# STM32F745 register map
File version: 1.6
CPU: CM7 r0p1, little endian, MPU, FPU, 4 interrupt priority bits
Registers are 32-bit, read-write, reset 0x0 unless marked. A register's access mark holds for its fields unless they carry their own. Offsets are from the block's base; [hi:lo] are bit positions.

## TIM6 — Basic timers
Base 0x40001000
Same registers: TIM7 0x40001400
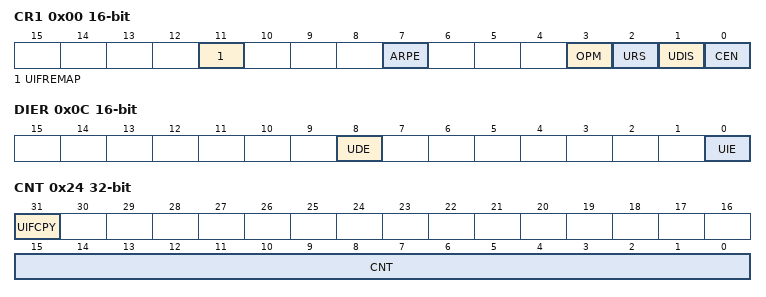
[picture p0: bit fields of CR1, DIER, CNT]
0x00 CR1 16-bit — control register 1
  [11] UIFREMAP — UIF status bit remapping
  [7] ARPE — Auto-reload preload enable
    0=Disabled (TIMx_APRR register is not buffered); 1=Enabled (TIMx_APRR register is buffered)
  [3] OPM — One-pulse mode
    0=Disabled (Counter is not stopped at update event); 1=Enabled (Counter stops counting at the next update event (clearing the CEN bit))
  [2] URS — Update request source
    0=AnyEvent (Any of counter overflow/underflow, setting UG, or update through slave mode, generates an update interrupt or DMA request); 1=CounterOnly (Only counter overflow/underflow generates an update interrupt or DMA request)
  [1] UDIS — Update disable
    0=Enabled (Update event enabled); 1=Disabled (Update event disabled)
  [0] CEN — Counter enable
    0=Disabled (Counter disabled); 1=Enabled (Counter enabled)
0x04 CR2 16-bit — control register 2
  [6:4] MMS — Master mode selection
    0=Reset (Use UG bit from TIMx_EGR register); 1=Enable (Use CNT bit from TIMx_CEN register); 2=Update (Use the update event)
0x0C DIER 16-bit — DMA/Interrupt enable register
  [8] UDE — Update DMA request enable
    0=Disabled (Update DMA request disabled); 1=Enabled (Update DMA request enabled)
  [0] UIE — Update interrupt enable
    0=Disabled (Update interrupt disabled); 1=Enabled (Update interrupt enabled)
0x10 SR 16-bit — status register
  [0] UIF write-0-clears — Update interrupt flag
    on read: 0=NoUpdateOccurred; 1=UpdatePending (Update interrupt pending) | on write: 0=Clear flag
0x14 EGR wo — event generation register
  [0] UG — Update generation
    1=Update (Re-initializes the timer counter and generates an update of the registers.)
0x24 CNT — counter
  [31] UIFCPY ro — UIF copy This bit is a read-only copy of the UIF bit of the TIMx_ISR register. If the UIFREMAP bit in the TIMxCR1 is reset, bit 31 is reserved and read at 0
  [15:0] CNT — Low counter value
0x24 CNT16 16-bit (alternate view of CNT) — 16-bit counter register
  [15:0] CNT — counter value
0x28 PSC 16-bit — prescaler
  [15:0] PSC — Prescaler value
0x2C ARR 16-bit reset 0xFFFF — auto-reload register
  [15:0] ARR — Low Auto-reload value

## Ethernet_MMC — Ethernet: MAC management counters
Base 0x40028100
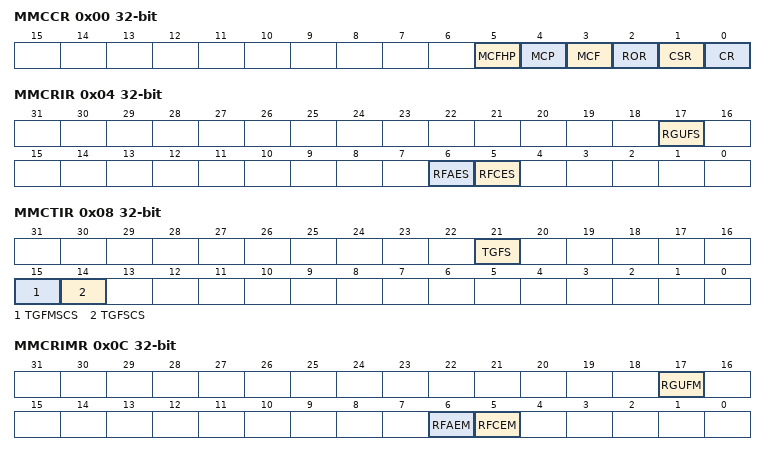
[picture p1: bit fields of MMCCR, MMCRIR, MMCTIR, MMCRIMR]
0x00 MMCCR — Ethernet MMC control register
  [5] MCFHP — MMC counter Full-Half preset
    0=AlmostHalf (When MCP is set, MMC counters are preset to almost-half value 0x7FFF_FFF0); 1=AlmostFull (When MCP is set, MMC counters are preset to almost-full value 0xFFFF_FFF0)
  [4] MCP — MMC counter preset
    1=Preset (MMC counters will be preset to almost full or almost half. Cleared automatically)
  [3] MCF — MMC counter freeze
    0=Unfrozen (All MMC counters update normally); 1=Frozen (All MMC counters frozen to their current value)
  [2] ROR — Reset on read
    0=Disabled (MMC counters do not reset on read); 1=Enabled (MMC counters reset to zero after read)
  [1] CSR — Counter stop rollover
    0=Disabled (Counters roll over to zero after reaching the maximum value); 1=Enabled (Counters do not roll over to zero after reaching the maximum value)
  [0] CR — Counter reset
    1=Reset all counters. Cleared automatically
0x04 MMCRIR — Ethernet MMC receive interrupt register
  [17] RGUFS — Received good Unicast frames status
  [6] RFAES — Received frames alignment error status
  [5] RFCES — Received frames CRC error status
0x08 MMCTIR ro — Ethernet MMC transmit interrupt register
  [21] TGFS — Transmitted good frames status
  [15] TGFMSCS — Transmitted good frames more than single collision status
  [14] TGFSCS — Transmitted good frames single collision status
0x0C MMCRIMR — Ethernet MMC receive interrupt mask register
  [17] RGUFM — Received good Unicast frames mask
    0=Unmasked (Received-good-unicast counter half-full interrupt enabled); 1=Masked (Received-good-unicast counter half-full interrupt disabled)
  [6] RFAEM — Received frames alignment error mask
    0=Unmasked (Received-alignment-error counter half-full interrupt enabled); 1=Masked (Received-alignment-error counter half-full interrupt disabled)
  [5] RFCEM — Received frame CRC error mask
    0=Unmasked (Received-crc-error counter half-full interrupt enabled); 1=Masked (Received-crc-error counter half-full interrupt disabled)
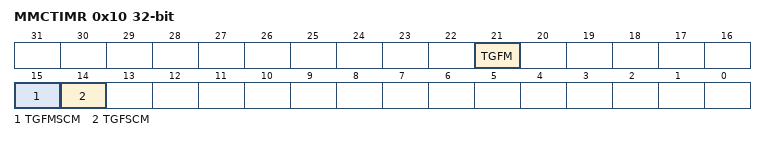
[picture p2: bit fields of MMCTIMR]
0x10 MMCTIMR — Ethernet MMC transmit interrupt mask register
  [21] TGFM — Transmitted good frames mask
    0=Unmasked (Transmitted-good counter half-full interrupt enabled); 1=Masked (Transmitted-good counter half-full interrupt disabled)
  [15] TGFMSCM — Transmitted good frames more than single collision mask
    0=Unmasked (Transmitted-good-multiple-collision half-full interrupt enabled); 1=Masked (Transmitted-good-multiple-collision half-full interrupt disabled)
  [14] TGFSCM — Transmitted good frames single collision mask
    0=Unmasked (Transmitted-good-single-collision half-full interrupt enabled); 1=Masked (Transmitted-good-single-collision half-full interrupt disabled)
0x4C MMCTGFSCCR ro — Ethernet MMC transmitted good frames after a single collision counter
  [31:0] TGFSCC — Transmitted good frames single collision counter
0x50 MMCTGFMSCCR ro — Ethernet MMC transmitted good frames after more than a single collision
  [31:0] TGFMSCC
0x68 MMCTGFCR ro — Ethernet MMC transmitted good frames counter register
  [31:0] TGFC — HTL
0x94 MMCRFCECR ro — Ethernet MMC received frames with CRC error counter register
  [31:0] RFCFC
0x98 MMCRFAECR ro — Ethernet MMC received frames with alignment error counter register
  [31:0] RFAEC
0xC4 MMCRGUFCR ro — MMC received good unicast frames counter register
  [31:0] RGUFC
